# EFR32MG24A620F1536IM40 register map
Vendor: Silicon Labs; Series: EFR32; File version: B
Registers are 32-bit, read-write, reset 0x0 unless marked. A register's access mark holds for its fields unless they carry their own. Offsets are from the block's base; [hi:lo] are bit positions; 'fields as' and 'values as' point back to an identical list.

## EMU_S — EMU_S Registers
Base 0x40004000
Same registers: EMU_NS 0x50004000
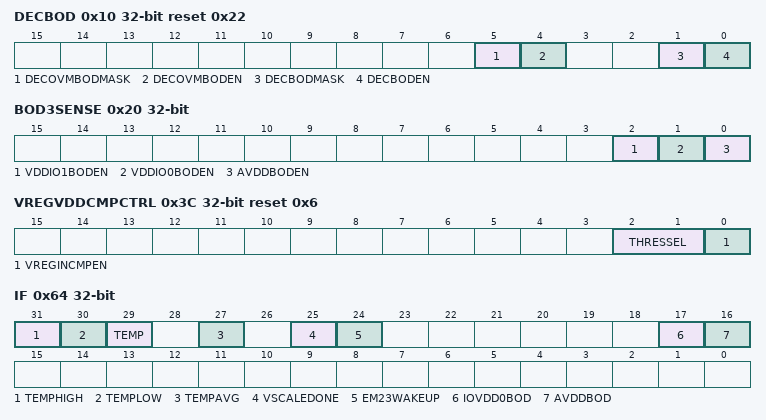
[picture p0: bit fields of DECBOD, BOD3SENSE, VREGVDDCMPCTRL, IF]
0x10 DECBOD reset 0x22
  [5] DECOVMBODMASK — Over Voltage Monitor Mask
  [4] DECOVMBODEN — Over Voltage Monitor enable
  [1] DECBODMASK
  [0] DECBODEN — DECBOD enable
0x20 BOD3SENSE
  [2] VDDIO1BODEN — VDDIO1 BOD enable
  [1] VDDIO0BODEN — VDDIO0 BOD enable
  [0] AVDDBODEN — AVDD BOD enable
0x3C VREGVDDCMPCTRL reset 0x6
  [2:1] THRESSEL — VREGVDD comparator threshold programming
  [0] VREGINCMPEN — VREGVDD comparator enable
0x40 PD1PARETCTRL
  [15:0] PD1PARETDIS — Disable PD1 Partial Retention
    1=PERIPHNORETAIN (Retain associated registers when in EM2/3); 2=RADIONORETAIN (Bit[1]. When set, do not retain RADIO associated registers when in EM2/3)
0x5C IPVERSION ro reset 0x3
0x60 LOCK wo reset 0xADE8
  [15:0] LOCKKEY
    0xADE8=UNLOCK (Unlock EMU register)
0x64 IF
  [31] TEMPHIGH — Temperature high Interrupt flag
  [30] TEMPLOW — Temperature low Interrupt flag
  [29] TEMP — Temperature Interrupt flag
  [27] TEMPAVG — Temperature Average Interrupt flag
  [25] VSCALEDONE — Vscale done Interrupt flag
  [24] EM23WAKEUP — EM23 Wake up Interrupt flag
  [17] IOVDD0BOD — VDDIO0 BOD Interrupt flag
  [16] AVDDBOD — AVDD BOD Interrupt flag
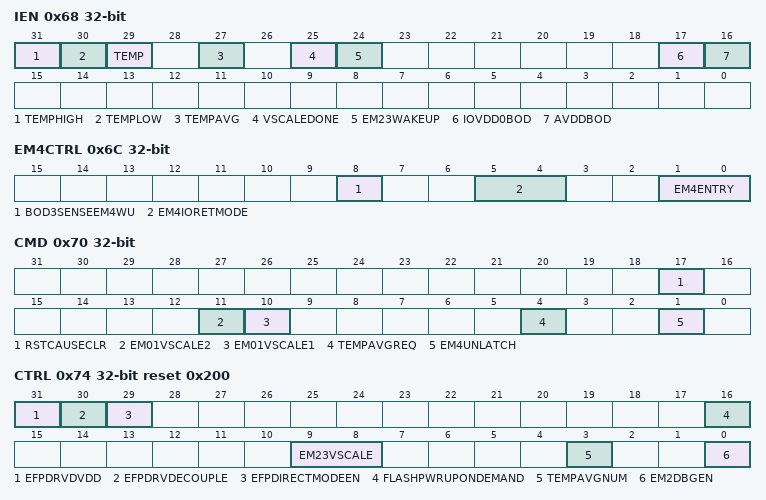
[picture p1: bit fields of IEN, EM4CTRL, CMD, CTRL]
0x68 IEN
  [31] TEMPHIGH — Temperature high Interrupt enable
  [30] TEMPLOW — Temperature low Interrupt enable
  [29] TEMP — Temperature Interrupt enable
  [27] TEMPAVG — Temperature Interrupt enable
  [25] VSCALEDONE — Vscale done Interrupt enable
  [24] EM23WAKEUP — EM23 Wake up Interrupt enable
  [17] IOVDD0BOD — VDDIO0 BOD Interrupt enable
  [16] AVDDBOD — AVDD BOD Interrupt enable
0x6C EM4CTRL
  [8] BOD3SENSEEM4WU — Set BOD3SENSE as EM4 wakeup
  [5:4] EM4IORETMODE — EM4 IO retention mode
    0=DISABLE (No Retention: Pads enter reset state when entering EM4); 1=EM4EXIT (Retention through EM4: Pads enter reset state when exiting EM4); 2=SWUNLATCH (Retention through EM4 and Wakeup: software writes UNLATCH register to remove retention)
  [1:0] EM4ENTRY — EM4 entry request
0x70 CMD wo
  [17] RSTCAUSECLR — Reset Cause Clear
  [11] EM01VSCALE2 — Scale voltage to Vscale2
  [10] EM01VSCALE1 — Scale voltage to Vscale1
  [4] TEMPAVGREQ — Temperature Average Request
  [1] EM4UNLATCH
0x74 CTRL reset 0x200
  [31] EFPDRVDVDD — EFP drives DVDD
  [30] EFPDRVDECOUPLE — EFP drives DECOUPLE
  [29] EFPDIRECTMODEEN — EFP Direct Mode Enable
  [16] FLASHPWRUPONDEMAND — Enable flash on demand wakeup
  [9:8] EM23VSCALE — EM2/EM3 Vscale
    0=VSCALE0 (VSCALE0. 0.9v); 1=VSCALE1 (VSCALE1. 1.0v); 2=VSCALE2 (VSCALE2. 1.1v)
  [3] TEMPAVGNUM — Averaged Temperature samples num
    0=N16 (16 measurements); 1=N64 (64 measurements)
  [0] EM2DBGEN — Enable debugging in EM2
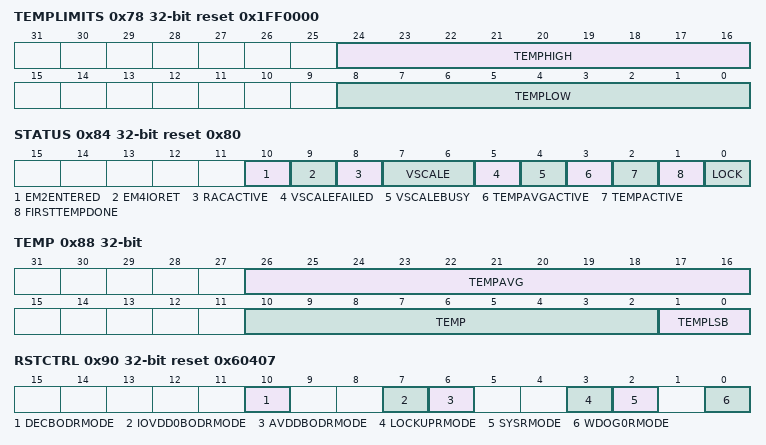
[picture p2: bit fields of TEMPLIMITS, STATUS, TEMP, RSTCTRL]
0x78 TEMPLIMITS reset 0x1FF0000
  [24:16] TEMPHIGH — Temp High limit
  [8:0] TEMPLOW — Temp Low limit
0x84 STATUS ro reset 0x80
  [10] EM2ENTERED
  [9] EM4IORET — EM4 IO retention status
  [8] RACACTIVE
  [7:6] VSCALE — Vscale status
    0=Voltage scaling set to 0.9v; 1=Voltage scaling set to 1.0v; 2=Voltage scaling set to 1.1v
  [5] VSCALEFAILED
  [4] VSCALEBUSY
  [3] TEMPAVGACTIVE — Temp Average active
  [2] TEMPACTIVE
  [1] FIRSTTEMPDONE
  [0] LOCK — Lock status
    0=UNLOCKED (All EMU lockable registers are unlocked.); 1=LOCKED (All EMU lockable registers are locked.)
0x88 TEMP ro
  [26:16] TEMPAVG — Averaged Temperature
  [10:2] TEMP — Temperature measured
  [1:0] TEMPLSB — Temperature measured decimal part
0x90 RSTCTRL reset 0x60407
  [10] DECBODRMODE — Enable DECBOD reset
    0=DISABLED (Reset request is blocked); 1=ENABLED (The entire device is reset)
  [7] IOVDD0BODRMODE — Enable VDDIO0 BOD reset
    0=DISABLED (Reset request is blocked); 1=ENABLED (The entire device is reset except some EMU registers)
  [6] AVDDBODRMODE — Enable AVDD BOD reset
    0=DISABLED (Reset Request is block); 1=ENABLED (The entire device is reset except some EMU registers)
  [3] LOCKUPRMODE — Enable M33 Lockup reset
    0=DISABLED (Reset Request is Block); 1=ENABLED (The entire device is reset except some EMU registers)
  [2] SYSRMODE — Enable M33 System reset
    0=DISABLED (Reset request is blocked); 1=ENABLED (Device is reset except some EMU registers)
  [0] WDOG0RMODE — Enable WDOG0 reset
    values as IOVDD0BODRMODE
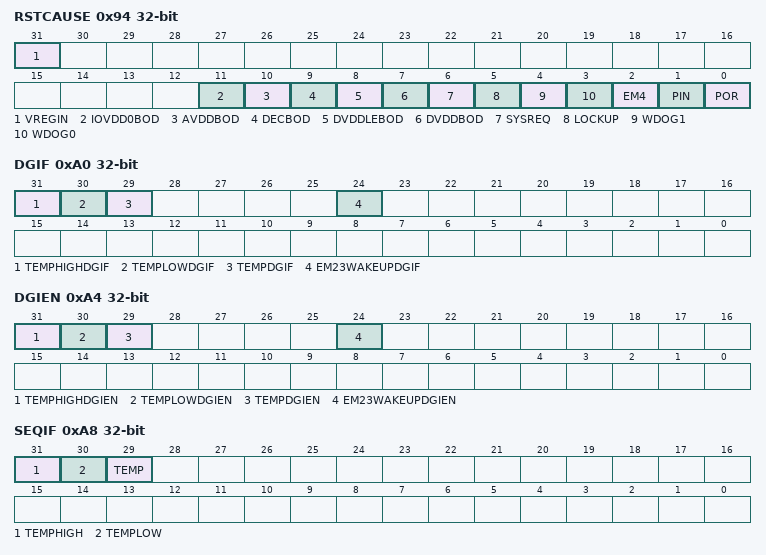
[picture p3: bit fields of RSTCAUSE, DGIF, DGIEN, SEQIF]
0x94 RSTCAUSE ro
  [31] VREGIN — DCDC VREGIN comparator
  [11] IOVDD0BOD — LEBOD2 Reset
  [10] AVDDBOD — LEBOD1 Reset
  [9] DECBOD — LVBOD Reset
  [8] DVDDLEBOD — LEBOD Reset
  [7] DVDDBOD — HVBOD Reset
  [6] SYSREQ — M33 Core Sys Reset
  [5] LOCKUP — M33 Core Lockup Reset
  [4] WDOG1 — Watchdog 1 Reset
  [3] WDOG0 — Watchdog 0 Reset
  [2] EM4 — EM4 Wakeup Reset
  [1] PIN — Pin Reset
  [0] POR — Power On Reset
0xA0 DGIF
  [31] TEMPHIGHDGIF — Temperature high Interrupt flag
  [30] TEMPLOWDGIF — Temperature low Interrupt flag
  [29] TEMPDGIF — Temperature Interrupt flag
  [24] EM23WAKEUPDGIF — EM23 Wake up Interrupt flag
0xA4 DGIEN
  [31] TEMPHIGHDGIEN — Temperature high Interrupt enable
  [30] TEMPLOWDGIEN — Temperature low Interrupt enable
  [29] TEMPDGIEN — Temperature Interrupt enable
  [24] EM23WAKEUPDGIEN — EM23 Wake up Interrupt enable
0xA8 SEQIF
  [31] TEMPHIGH — Temperature high Interrupt flag
  [30] TEMPLOW — Temperature low Interrupt flag
  [29] TEMP — Temperature Interrupt flag
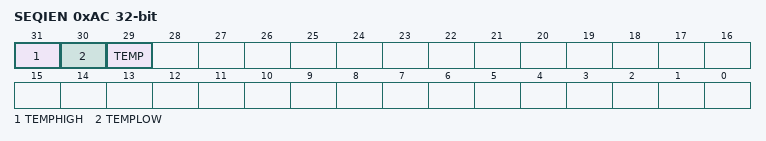
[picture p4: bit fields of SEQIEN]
0xAC SEQIEN
  [31] TEMPHIGH — Temperature high Interrupt enable
  [30] TEMPLOW — Temperature low Interrupt enable
  [29] TEMP — Temperature Interrupt enable
0x100 EFPIF
  [0] EFPIF — EFP Interrupt Flag
0x104 EFPIEN
  [0] EFPIEN — EFP Interrupt enable
